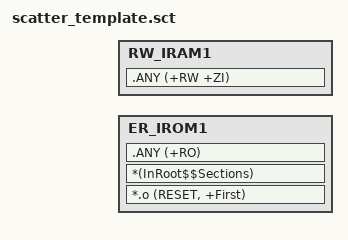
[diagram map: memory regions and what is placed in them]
; ===========================================================================
; Keil AC5 scatter template - generated by tools/gen_keil.py
;
; 起始地址和区域大小来自手写 board_config.h，由 gen_keil.py 读取并替换。
; 代码区 = BOARD_CODE_FLASH_SIZE_KB，必须停在 NVM 之前。
;
; LR_IROM1 是加载区域（Flash），ER_IROM1 是执行区域（同地址）；
; RW_IRAM1 承载可读写数据和零初始化数据。
;
; CCM 故意不使用（DMA 无法访问），因此不在这里定义执行区域。
; ===========================================================================

LR_IROM1 @FLASH_ORIGIN@ @FLASH_SIZE@ {
  ER_IROM1 @FLASH_ORIGIN@ @FLASH_SIZE@ {
    ; RESET 段必须放在最前：Cortex-M 从 Flash 起始读取 MSP 和复位向量。
    *.o (RESET, +First)
    ; ARM 链接器内部段（如 __main 需要的初始化信息）。
    *(InRoot$$Sections)
    ; 其余只读代码/常量。
    .ANY (+RO)
  }

  RW_IRAM1 @RAM_ORIGIN@ @RAM_SIZE@ {
    ; .data（初值从 Flash 拷贝）和 .bss（ZI，零初始化）。
    .ANY (+RW +ZI)
  }
}
